# RL7005_IP_SVD register map
Vendor: Realtek
Registers are 32-bit, read-write, reset 0x0 unless marked. A register's access mark holds for its fields unless they carry their own. Offsets are from the block's base; [hi:lo] are bit positions; {n}, {i} and the like mark numbered series.

## IPC0_REG
Base 0x40815000
Same registers: IPC1_REG 0x40815080
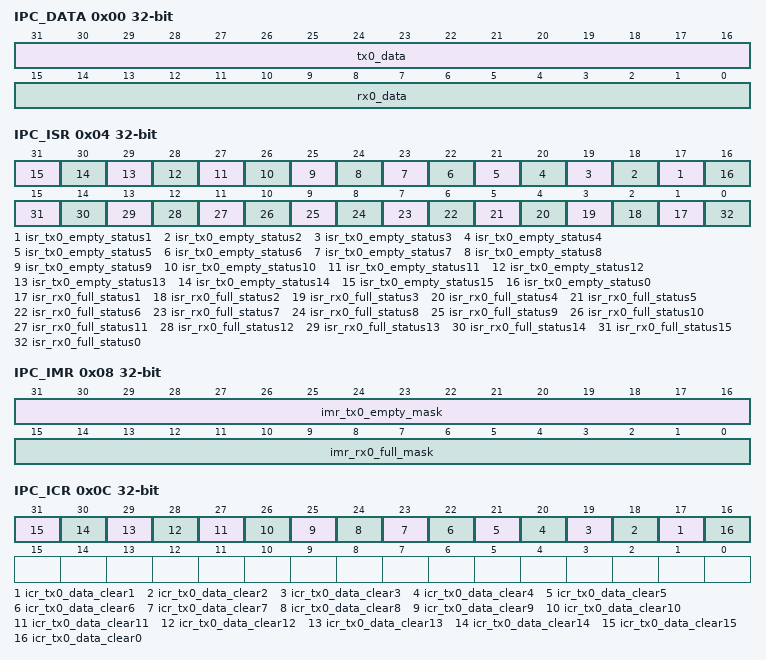
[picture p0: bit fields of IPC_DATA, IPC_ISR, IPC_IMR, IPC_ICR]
0x00 IPC_DATA access per field — Tx_Rx Register
  [31:16] tx0_data rw — After preparing descriptor, data and corresponding memory, 1: Writing 1 to the Tx data register (tx0_data) channel x bit, and the data will be mapped to the CPU0's RX data register (rx0_data) channel x bit. And the corresponding Rx full status bit in REG_ISR_CPU0 will be set. 0: Writing 0 has no effect. If the corresponding Rx full status bit in REG_ISR_CPU0 (eg.isr_rx0_full_status6) is cleared, the corresponding bit in tx0_data will be cleaned automatically.
  [15:0] rx0_data ro — Rx data automatically maps data from tx0_data of CPU0
0x04 IPC_ISR ro — Interrupt Empty Full Status Register
  [n+16] isr_tx0_empty_status{n} (n=1..15) — Refer to the description of the isr_tx0_empty_status0
  [16] isr_tx0_empty_status0 — Tx channel 0 empty interrupt status of CPU1 transmit to CPU0. If the corresponding Rx full status bit in REG_ISR_CPU0 (eg.isr_rx0_full_status0) is cleared, the corresponding Tx empty status bit will be set automatically. It will be cleared by software writing 1.
  [n] isr_rx0_full_status{n} (n=1..15) — Refer to the description of the isr_rx0_full_status0.
  [0] isr_rx0_full_status0 — Rx channel 0 full interrupt status of CPU1. The corresponding Rx full status bit will be set by CPU0's Tx data register (tx0_data) channel 0. It will be cleared by software writing 1.
0x08 IPC_IMR — Interrupt Empty Full Mask Register
  [31:16] imr_tx0_empty_mask — 0: Mask Tx Channel x empty interrupt of CPU1 transmit to CPU0 1: Unmask Tx Channel x empty interrupt of CPU1 transmit to CPU0
  [15:0] imr_rx0_full_mask — 0: Mask Rx Channel x full interrupt of CPU1 received from CPU0 1: Unmask Rx Channel x full interrupt of CPU1 received from CPU0
0x0C IPC_ICR access per field — Clear Tx Register
  [n+16] icr_tx0_data_clear{n} ro (n=1..15) — Refer to the description of the icr_tx0_data_clear0.
  [16] icr_tx0_data_clear0 ro — 0: Writing 0 has no effect. 1: Clear the Tx data register (tx0_data) channel 0 bit.
0x20 IPC_SEM_0 ro
  [31:0] sem_0_data — it is used to indicate who owns this semaphore .
0x24 IPC_SEM_1 ro
  [31:0] sem_1_data — it is used to indicate who owns this semaphore .
{0x28+4i} IPC_SEM_CPUID{i} ro (i=0..3)
  [31:0] sem_cpuid{i}_data — it is used to indicate cpuid of this semaphore .
0x38 IPC_DUMMY
  [15:0] dummy — dummy reg

## LEDC_REG
Base 0x4080B200
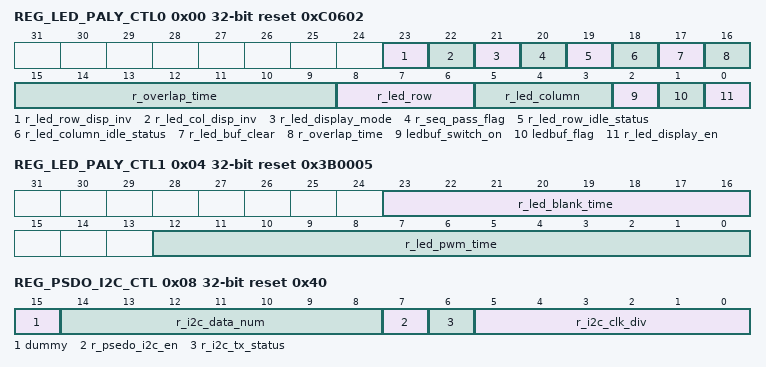
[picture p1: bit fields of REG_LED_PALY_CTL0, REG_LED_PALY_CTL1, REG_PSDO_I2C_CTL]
0x00 REG_LED_PALY_CTL0 access per field reset 0xC0602
  [23] r_led_row_disp_inv rw — 1: inverse row output logic of the current display mode; 0: default row output logic of the current display mode
  [22] r_led_col_disp_inv rw — 1: inverse column output logic of the current display mode; 0: default column output logic of the current display mode
  [21] r_led_display_mode rw — 1: show rows in sequence 0: show columns in sequence
  [20] r_seq_pass_flag ro — 1: indicate 0x0c[31:0] sequence check pass, clear 0 when read
  [19] r_led_row_idle_status rw — 1: output 0: floating
  [18] r_led_column_idle_status rw — 1: output 0: floating
  [17] r_led_buf_clear wo — write 1 generate one pulse. Clear and reset ram data
  [16:9] r_overlap_time rw — time is r_overlap_time +1, delay beweent stage, unit 4M clock
  [8:6] r_led_row rw — led row number - 1
  [5:3] r_led_column rw — led column number - 1
  [2] ledbuf_switch_on ro — 1: sw trigger hw switch ram; 0: hw switch finish
  [1] ledbuf_flag ro — 1: display data of ram1; 0: display data of ram0. HW check in when display enable and sw trigger hw switch ram
  [0] r_led_display_en rw — 1: enable led driver to display;0:disable led driver to display
0x04 REG_LED_PALY_CTL1 reset 0x3B0005
  [23:16] r_led_blank_time — time is r_led_blank_time +1 , unit 4M clock
  [12:0] r_led_pwm_time — one stage time of a frame, unit 255*250ns
0x08 REG_PSDO_I2C_CTL access per field reset 0x40
  [15] dummy rw
  [14:8] r_i2c_data_num rw — psdo i2c data num, unit: byte
  [7] r_psedo_i2c_en rw — indicate psedo i2c in working, only when this bit=1 can access psedo i2c ram
  [6] r_i2c_tx_status ro — 1: psdo i2c is idle, 0: psdo i2c is working
  [5:0] r_i2c_clk_div rw — clock division factor = r_i2c_clk_div * 2, minimum value is 2
0x0C REG_SEQUENCE_CHECK0
  [31:0] r_seq_chk0 — sequence check, when this field first write 0x69696969, then write 0x96969696, tirgger led/i2c work
0x10 REG_SEQUENCE_CHECK1
  [31:0] r_seq_chk1 — register protect sequence check, when this field = 0xa5a5a5a5, enable access protect register
0x80 REG_LED_RAM
  [31:0] r_led_ram_data — 4100_9280~4100_92FF 128bytes 4100_9280~4100_92BF,64bytes used for led display 4100_9280~4100_92C0,65bytes used for psdo i2c
